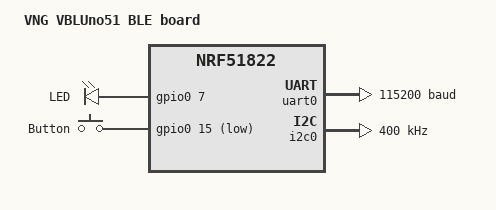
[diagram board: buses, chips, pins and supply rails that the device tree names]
/*
 * Copyright (c) 2017 VNG IoT Lab Limited
 *
 * SPDX-License-Identifier: Apache-2.0
 */

/dts-v1/;
#include <nordic/nrf51822_qfac.dtsi>
#include "nrf51_vbluno51-pinctrl.dtsi"

/ {
	model = "VNG VBLUno51 BLE board";
	compatible = "vng,vbluno51";

	chosen {
		zephyr,console = &uart0;
		zephyr,shell-uart = &uart0;
		zephyr,bt-mon-uart = &uart0;
		zephyr,bt-c2h-uart = &uart0;
		zephyr,sram = &sram0;
		zephyr,flash = &flash0;
	};

	/* These aliases are provided for compatibility with samples */
	aliases {
		led0 = &led0;
		sw0 = &button0;
	};

	leds {
		compatible = "gpio-leds";
		/* green led */
		led0: led_0 {
			gpios = <&gpio0 7 0>;
			label = "LED";
		};
	};

	buttons {
		/* Push button switch 0 KEY1 */
		compatible = "gpio-keys";
		button0: button_0 {
			/* gpio flags need validation */
			gpios = <&gpio0 15 GPIO_ACTIVE_LOW>;
			label = "Button";
		};
	};
};

&gpiote {
	status = "okay";
};

&gpio0 {
	status = "okay";
};

&uart0 {
	current-speed = <115200>;
	status = "okay";
	pinctrl-0 = <&uart0_default>;
	pinctrl-1 = <&uart0_sleep>;
	pinctrl-names = "default", "sleep";
};

&i2c0 {
	status = "okay";
	clock-frequency = <I2C_BITRATE_FAST>;
	pinctrl-0 = <&i2c0_default>;
	pinctrl-1 = <&i2c0_sleep>;
	pinctrl-names = "default", "sleep";
};
